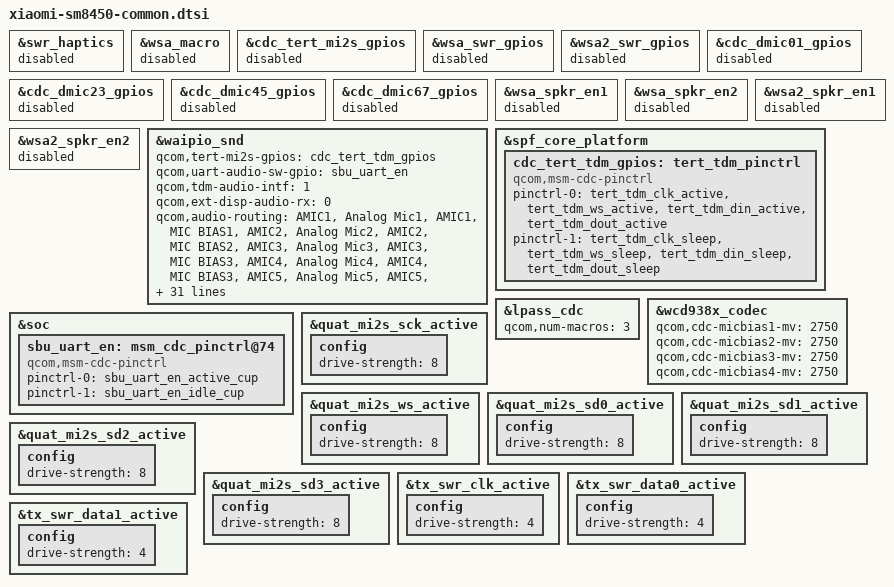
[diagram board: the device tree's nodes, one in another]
#include "waipio-audio-overlay.dtsi"

&swr_haptics {
	status = "disabled";
};

&wsa_macro {
	status = "disabled";
};

&cdc_tert_mi2s_gpios {
	status = "disabled";
};

&wsa_swr_gpios {
	status = "disabled";
};

&wsa2_swr_gpios {
	status = "disabled";
};

&cdc_dmic01_gpios {
	status = "disabled";
};

&cdc_dmic23_gpios {
	status = "disabled";
};

&cdc_dmic45_gpios {
	status = "disabled";
};

&cdc_dmic67_gpios {
	status = "disabled";
};

&wsa_spkr_en1 {
	status = "disabled";
};

&wsa_spkr_en2 {
	status = "disabled";
};

&wsa2_spkr_en1 {
	status = "disabled";
};

&wsa2_spkr_en2 {
	status = "disabled";
};


&waipio_snd {
	qcom,tert-mi2s-gpios = <&cdc_tert_tdm_gpios>;
	qcom,uart-audio-sw-gpio = <&sbu_uart_en>;
	qcom,tdm-audio-intf = <1>;
	qcom,ext-disp-audio-rx = <0>;
	qcom,audio-routing =
		"AMIC1", "Analog Mic1",
		"AMIC1", "MIC BIAS1",
		"AMIC2", "Analog Mic2",
		"AMIC2", "MIC BIAS2",
		"AMIC3", "Analog Mic3",
		"AMIC3", "MIC BIAS3",
		"AMIC4", "Analog Mic4",
		"AMIC4", "MIC BIAS3",
		"AMIC5", "Analog Mic5",
		"AMIC5", "MIC BIAS4",
		"VA AMIC1", "Analog Mic1",
		"VA AMIC1", "VA MIC BIAS1",
		"VA AMIC2", "Analog Mic2",
		"VA AMIC2", "VA MIC BIAS2",
		"VA AMIC3", "Analog Mic3",
		"VA AMIC3", "VA MIC BIAS3",
		"VA AMIC4", "Analog Mic4",
		"VA AMIC4", "VA MIC BIAS3",
		"VA AMIC5", "Analog Mic5",
		"VA AMIC5", "VA MIC BIAS4",
		"TX DMIC0", "Digital Mic0",
		"Digital Mic0", "MIC BIAS3",
		"TX DMIC1", "Digital Mic1",
		"Digital Mic1", "MIC BIAS3",
		"TX DMIC2", "Digital Mic2",
		"Digital Mic2", "MIC BIAS1",
		"TX DMIC3", "Digital Mic3",
		"Digital Mic3", "MIC BIAS1",
		"IN1_HPHL", "HPHL_OUT",
		"IN2_HPHR", "HPHR_OUT",
		"IN3_AUX", "AUX_OUT",
		"RX_TX DEC0_INP", "TX DEC0 MUX",
		"RX_TX DEC1_INP", "TX DEC1 MUX",
		"RX_TX DEC2_INP", "TX DEC2 MUX",
		"RX_TX DEC3_INP", "TX DEC3 MUX",
		"TX SWR_INPUT", "WCD_TX_OUTPUT",
		"VA SWR_INPUT", "VA_SWR_CLK",
		"VA SWR_INPUT", "WCD_TX_OUTPUT",
		"VA_AIF1 CAP", "VA_SWR_CLK",
		"VA_AIF2 CAP", "VA_SWR_CLK",
		"VA_AIF3 CAP", "VA_SWR_CLK",
		"VA DMIC0", "Digital Mic0",
		"VA DMIC1", "Digital Mic1",
		"VA DMIC2", "Digital Mic2",
		"VA DMIC3", "Digital Mic3",
		"Digital Mic0", "VA MIC BIAS3",
		"Digital Mic1", "VA MIC BIAS3",
		"Digital Mic2", "VA MIC BIAS1",
		"Digital Mic3", "VA MIC BIAS1";
	qcom,msm-mbhc-usbc-audio-supported = <1>;
	qcom,msm-mbhc-hphl-swh = <0>;
	qcom,msm-mbhc-gnd-swh = <0>;
	qcom,wsa-max-devs = <0>;
	qcom,upd_lpass_reg_addr = <0x418 0x33b0300>;
};

&spf_core_platform {
	cdc_tert_tdm_gpios: tert_tdm_pinctrl {
		status= "ok";
		compatible = "qcom,msm-cdc-pinctrl";
		pinctrl-names = "aud_active", "aud_sleep";
		pinctrl-0 = <&tert_tdm_clk_active &tert_tdm_ws_active
				&tert_tdm_din_active &tert_tdm_dout_active>;
		pinctrl-1 = <&tert_tdm_clk_sleep &tert_tdm_ws_sleep
				&tert_tdm_din_sleep &tert_tdm_dout_sleep>;
		#gpio-cells = <0>;
	};
};

&lpass_cdc {
	qcom,num-macros = <3>;
};

&soc {
	sbu_uart_en: msm_cdc_pinctrl@74 {
		compatible = "qcom,msm-cdc-pinctrl";
		pinctrl-names = "aud_active", "aud_sleep";
		pinctrl-0 = <&sbu_uart_en_active_cup>;
		pinctrl-1 = <&sbu_uart_en_idle_cup>;
		#gpio-cells = <0>;
	};
};

&wcd938x_codec {
	qcom,cdc-micbias1-mv = <2750>;
	qcom,cdc-micbias2-mv = <2750>;
	qcom,cdc-micbias3-mv = <2750>;
	qcom,cdc-micbias4-mv = <2750>;
};

&quat_mi2s_sck_active {
	config {
		drive-strength = <8>;   /* 8 mA */
	};
};

&quat_mi2s_ws_active {
	config {
		drive-strength = <8>;   /* 8 mA */
	};
};

&quat_mi2s_sd0_active {
	config {
		drive-strength = <8>;   /* 8 mA */
	};
};

&quat_mi2s_sd1_active {
	config {
		drive-strength = <8>;   /* 8 mA */
	};
};

&quat_mi2s_sd2_active {
	config {
		drive-strength = <8>;   /* 8 mA */
	};
};

&quat_mi2s_sd3_active {
	config {
		drive-strength = <8>;   /* 8 mA */
	};
};

&tx_swr_clk_active {
	config {
		drive-strength = <4>;
	};
};

&tx_swr_data0_active {
	config {
		drive-strength = <4>;
	};
};

&tx_swr_data1_active {
	config {
		drive-strength = <4>;
	};
};
